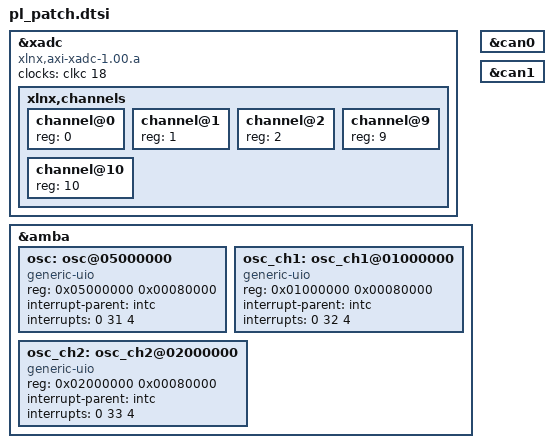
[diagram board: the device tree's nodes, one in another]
/*
 * Zynq XADC configuration
*/

&xadc {
        compatible = "xlnx,axi-xadc-1.00.a";
        clocks = <&clkc 18>;
        xlnx,channels {
                #address-cells = <1>;
                #size-cells = <0>;
                channel@0 {
                        reg = <0>;
                };
                channel@1 {
                        reg = <1>;
                };
                channel@2 {
                        reg = <2>;
                };
                channel@9 {
                        reg = <9>;
                };
                channel@10 {
                        reg = <10>;
                };
        };
};

&amba {
        osc: osc@05000000 {
                compatible = "generic-uio";
                /*
                 * Keep the legacy aggregate IRQ UIO separate from the
                 * per-channel UIO devices and from api@40000000.
                 */
                reg = <0x05000000 0x00080000>;
                reg-names = "buffer";
                interrupt-names = "intr";
                interrupt-parent = <&intc>;
                interrupts = <0 31 4>;
                status = "okay";
        };

        osc_ch1: osc_ch1@01000000 {
                compatible = "generic-uio";
                reg = <0x01000000 0x00080000>;
                reg-names = "buffer";
                interrupt-names = "intr";
                interrupt-parent = <&intc>;
                interrupts = <0 32 4>;
                status = "okay";
        };

        osc_ch2: osc_ch2@02000000 {
                compatible = "generic-uio";
                reg = <0x02000000 0x00080000>;
                reg-names = "buffer";
                interrupt-names = "intr";
                interrupt-parent = <&intc>;
                interrupts = <0 33 4>;
                status = "okay";
        };
};

/ {
         fragment@9 {
                target = <&can0>;
                overlay9: __overlay__ {
                        status = "okay";
                };
        };

        fragment@10 {
                target = <&can1>;
                overlay10: __overlay__ {
                        status = "okay";
                };
        };
};
